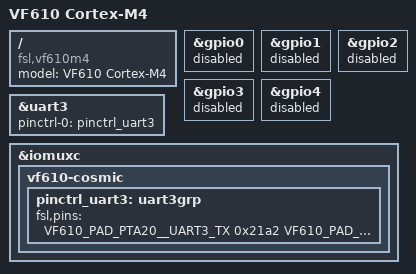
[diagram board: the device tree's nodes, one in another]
/dts-v1/;
#include "vf610m4.dtsi"
/ {
	model = "VF610 Cortex-M4";
	compatible = "fsl,vf610m4";
};
&gpio0 {
	status = "disabled";
};
&gpio1 {
	status = "disabled";
};
&gpio2 {
	status = "disabled";
};
&gpio3 {
	status = "disabled";
};
&gpio4 {
	status = "disabled";
};
&uart3 {
	pinctrl-names = "default";
	pinctrl-0 = <&pinctrl_uart3>;
	status = "okay";
};
&iomuxc {
	vf610-cosmic {
		pinctrl_uart3: uart3grp {
			fsl,pins = <
				VF610_PAD_PTA20__UART3_TX		0x21a2
				VF610_PAD_PTA21__UART3_RX		0x21a1
			>;
		};
	};
};
